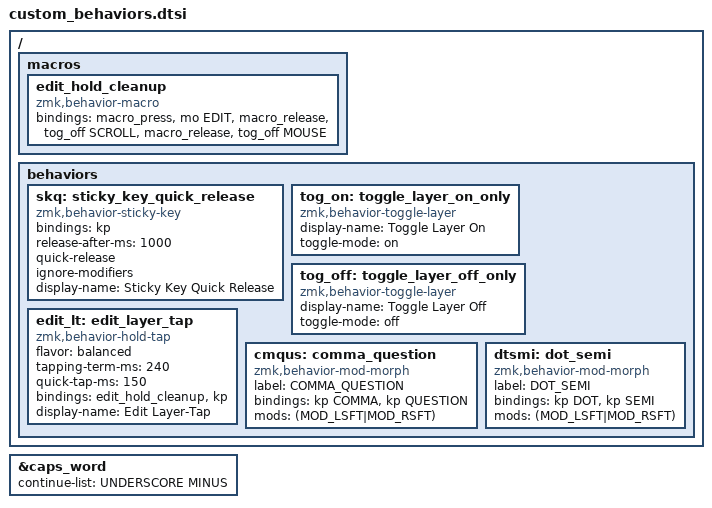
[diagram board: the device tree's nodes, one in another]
/ {
    macros {
        edit_hold_cleanup: edit_hold_cleanup {
            compatible = "zmk,behavior-macro";
            #binding-cells = <0>;
            bindings
                = <&macro_press &mo EDIT>
                , <&macro_release &tog_off SCROLL>
                , <&macro_release &tog_off MOUSE>
                ;
        };
    };

    behaviors {
        skq: sticky_key_quick_release {
            compatible = "zmk,behavior-sticky-key";
            #binding-cells = <1>;
            bindings = <&kp>;
            release-after-ms = <1000>;
            quick-release;
            ignore-modifiers;
            display-name = "Sticky Key Quick Release";
        };

        tog_on: toggle_layer_on_only {
            compatible = "zmk,behavior-toggle-layer";
            #binding-cells = <1>;
            display-name = "Toggle Layer On";
            toggle-mode = "on";
        };

        tog_off: toggle_layer_off_only {
            compatible = "zmk,behavior-toggle-layer";
            #binding-cells = <1>;
            display-name = "Toggle Layer Off";
            toggle-mode = "off";
        };

        edit_lt: edit_layer_tap {
            compatible = "zmk,behavior-hold-tap";
            #binding-cells = <2>;
            flavor = "balanced";
            tapping-term-ms = <240>;
            quick-tap-ms = <150>;
            bindings = <&edit_hold_cleanup>, <&kp>;
            display-name = "Edit Layer-Tap";
        };

        cmqus: comma_question {
            compatible = "zmk,behavior-mod-morph";
            label = "COMMA_QUESTION";
            #binding-cells = <0>;
            bindings = <&kp COMMA>, <&kp QUESTION>;
            mods = <(MOD_LSFT|MOD_RSFT)>;
        };

        dtsmi: dot_semi {
            compatible = "zmk,behavior-mod-morph";
            label = "DOT_SEMI";
            #binding-cells = <0>;
            bindings = <&kp DOT>, <&kp SEMI>;
            mods = <(MOD_LSFT|MOD_RSFT)>;
        };
    };
};

&caps_word {
    continue-list = <UNDERSCORE MINUS>;
};
